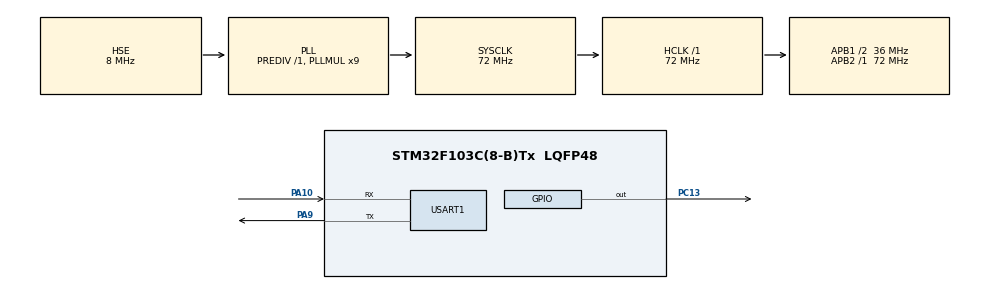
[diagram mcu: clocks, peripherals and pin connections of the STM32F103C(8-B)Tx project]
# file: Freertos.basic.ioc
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Dma.Request0=USART1_RX
Dma.Request1=USART1_TX
Dma.USART1_RX.0.Direction=DMA_PERIPH_TO_MEMORY
Dma.USART1_RX.0.Instance=DMA1_Channel5
Dma.USART1_RX.0.MemDataAlignment=DMA_MDATAALIGN_BYTE
Dma.USART1_RX.0.MemInc=DMA_MINC_ENABLE
Dma.USART1_RX.0.Mode=DMA_NORMAL
Dma.USART1_RX.0.PeriphDataAlignment=DMA_PDATAALIGN_BYTE
Dma.USART1_RX.0.PeriphInc=DMA_PINC_DISABLE
Dma.USART1_RX.0.Priority=DMA_PRIORITY_LOW
Dma.USART1_TX.1.Direction=DMA_MEMORY_TO_PERIPH
Dma.USART1_TX.1.Instance=DMA1_Channel4
Dma.USART1_TX.1.MemDataAlignment=DMA_MDATAALIGN_BYTE
Dma.USART1_TX.1.MemInc=DMA_MINC_ENABLE
Dma.USART1_TX.1.Mode=DMA_NORMAL
Dma.USART1_TX.1.PeriphDataAlignment=DMA_PDATAALIGN_BYTE
Dma.USART1_TX.1.PeriphInc=DMA_PINC_DISABLE
Dma.USART1_TX.1.Priority=DMA_PRIORITY_LOW
FREERTOS.Queues01=myQueue01,16,uint16_t,0,Dynamic,NULL,NULL
FREERTOS.Tasks01=ledTask,24,128,StartledTask,Default,NULL,Dynamic,NULL,NULL;connect_task,24,128,Startconnect_Task,Default,NULL,Dynamic,NULL,NULL
FREERTOS.configUSE_PREEMPTION=0
Mcu.Family=STM32F1
Mcu.Name=STM32F103C(8-B)Tx
Mcu.Package=LQFP48
NVIC.DMA1_Channel4_IRQn=true\:5\:0\:false\:false\:true\:true\:false\:true\:true
NVIC.DMA1_Channel5_IRQn=true\:5\:0\:false\:false\:true\:true\:false\:true\:true
NVIC.PriorityGroup=NVIC_PRIORITYGROUP_4
NVIC.TIM4_IRQn=true\:15\:0\:false\:false\:true\:false\:false\:true\:true
NVIC.TimeBase=TIM4_IRQn
NVIC.TimeBaseIP=TIM4
NVIC.USART1_IRQn=true\:5\:0\:false\:false\:true\:true\:true\:true\:true
PA10.Mode=Asynchronous
PA10.Signal=USART1_RX
PA13.Mode=Serial_Wire
PA13.Signal=SYS_JTMS-SWDIO
PA14.Mode=Serial_Wire
PA14.Signal=SYS_JTCK-SWCLK
PA9.Mode=Asynchronous
PA9.Signal=USART1_TX
PC13-TAMPER-RTC.PinState=GPIO_PIN_RESET
PC13-TAMPER-RTC.Signal=GPIO_Output
PD0-OSC_IN.Mode=HSE-External-Oscillator
PD0-OSC_IN.Signal=RCC_OSC_IN
PD1-OSC_OUT.Mode=HSE-External-Oscillator
PD1-OSC_OUT.Signal=RCC_OSC_OUT
ProjectManager.HeapSize=0x200
ProjectManager.StackSize=0x400
ProjectManager.TargetToolchain=CMake
RCC.AHBFreq_Value=72000000
RCC.APB1CLKDivider=RCC_HCLK_DIV2
RCC.APB1Freq_Value=36000000
RCC.APB1TimFreq_Value=72000000
RCC.APB2Freq_Value=72000000
RCC.APB2TimFreq_Value=72000000
RCC.HCLKFreq_Value=72000000
RCC.PLLMUL=RCC_PLL_MUL9
RCC.PLLSourceVirtual=RCC_PLLSOURCE_HSE
RCC.SYSCLKFreq_VALUE=72000000
RCC.SYSCLKSource=RCC_SYSCLKSOURCE_PLLCLK
RCC.USBFreq_Value=72000000
USART1.VirtualMode=VM_ASYNC
VP_FREERTOS_VS_CMSIS_V2.Mode=CMSIS_V2
VP_SYS_VS_tim4.Mode=TIM4
board=custom

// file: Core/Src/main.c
/* USER CODE BEGIN Header */
/**
  ******************************************************************************
  * @file           : main.c
  * @brief          : Main program body
  ******************************************************************************
  * @attention
  *
  * Copyright (c) 2025 STMicroelectronics.
  * All rights reserved.
  *
  * This software is licensed under terms that can be found in the LICENSE file
  * in the root directory of this software component.
  * If no LICENSE file comes with this software, it is provided AS-IS.
  *
  ******************************************************************************
  */
/* USER CODE END Header */
#include "main.h"
#include "cmsis_os.h"
#include "dma.h"
#include "usart.h"
#include "gpio.h"

void SystemClock_Config(void);
void MX_FREERTOS_Init(void);

int main(void)
{

  /* MCU Configuration--------------------------------------------------------*/

  /* Reset of all peripherals, Initializes the Flash interface and the Systick. */
  HAL_Init();

  /* Configure the system clock */
  SystemClock_Config();

  /* Initialize all configured peripherals */
  MX_GPIO_Init();
  MX_DMA_Init();
  MX_USART1_UART_Init();

  /* Init scheduler */
  osKernelInitialize();  /* Call init function for freertos objects (in cmsis_os2.c) */
  MX_FREERTOS_Init();

  /* Start scheduler */
  osKernelStart();

  /* We should never get here as control is now taken by the scheduler */

  /* Infinite loop */
  while (1)
  {

  }
}

void SystemClock_Config(void)
{
  RCC_OscInitTypeDef RCC_OscInitStruct = {0};
  RCC_ClkInitTypeDef RCC_ClkInitStruct = {0};

  /** Initializes the RCC Oscillators according to the specified parameters
  * in the RCC_OscInitTypeDef structure.
  */
  RCC_OscInitStruct.OscillatorType = RCC_OSCILLATORTYPE_HSE;
  RCC_OscInitStruct.HSEState = RCC_HSE_ON;
  RCC_OscInitStruct.HSEPredivValue = RCC_HSE_PREDIV_DIV1;
  RCC_OscInitStruct.HSIState = RCC_HSI_ON;
  RCC_OscInitStruct.PLL.PLLState = RCC_PLL_ON;
  RCC_OscInitStruct.PLL.PLLSource = RCC_PLLSOURCE_HSE;
  RCC_OscInitStruct.PLL.PLLMUL = RCC_PLL_MUL9;
  if (HAL_RCC_OscConfig(&RCC_OscInitStruct) != HAL_OK)
  {
    Error_Handler();
  }

  /** Initializes the CPU, AHB and APB buses clocks
  */
  RCC_ClkInitStruct.ClockType = RCC_CLOCKTYPE_HCLK|RCC_CLOCKTYPE_SYSCLK
                              |RCC_CLOCKTYPE_PCLK1|RCC_CLOCKTYPE_PCLK2;
  RCC_ClkInitStruct.SYSCLKSource = RCC_SYSCLKSOURCE_PLLCLK;
  RCC_ClkInitStruct.AHBCLKDivider = RCC_SYSCLK_DIV1;
  RCC_ClkInitStruct.APB1CLKDivider = RCC_HCLK_DIV2;
  RCC_ClkInitStruct.APB2CLKDivider = RCC_HCLK_DIV1;

  if (HAL_RCC_ClockConfig(&RCC_ClkInitStruct, FLASH_LATENCY_2) != HAL_OK)
  {
    Error_Handler();
  }
}

void HAL_TIM_PeriodElapsedCallback(TIM_HandleTypeDef *htim)
{
  if (htim->Instance == TIM4)
  {
    HAL_IncTick();
  }
}

void Error_Handler(void)
{
  __disable_irq();
  while (1)
  {
  }
}

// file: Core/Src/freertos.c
/* USER CODE BEGIN Header */
/**
  ******************************************************************************
  * File Name          : freertos.c
  * Description        : Code for freertos applications
  ******************************************************************************
  * @attention
  *
  * Copyright (c) 2025 STMicroelectronics.
  * All rights reserved.
  *
  * This software is licensed under terms that can be found in the LICENSE file
  * in the root directory of this software component.
  * If no LICENSE file comes with this software, it is provided AS-IS.
  *
  ******************************************************************************
  */
/* USER CODE END Header */

#include "FreeRTOS.h"
#include "cmsis_os2.h"
#include "projdefs.h"
#include "task.h"
#include "main.h"
#include "cmsis_os.h"

/* USER CODE BEGIN Includes */
#include "math.h"
#include "usart.h"
#include <stdint.h>
#include "queue.h"
/* USER CODE END Includes */

/* USER CODE BEGIN PTD */
uint8_t rx_buffer[3];
volatile uint8_t rxdone = 0;
/* USER CODE END PTD */

/* Definitions for ledTask */
osThreadId_t ledTaskHandle;
const osThreadAttr_t ledTask_attributes = {
  .name = "ledTask",
  .stack_size = 128 * 4,
  .priority = (osPriority_t) osPriorityNormal,
};
/* Definitions for connect_task */
osThreadId_t connect_taskHandle;
const osThreadAttr_t connect_task_attributes = {
  .name = "connect_task",
  .stack_size = 128 * 4,
  .priority = (osPriority_t) osPriorityNormal,
};
/* Definitions for myQueue01 */
osMessageQueueId_t myQueue01Handle;
const osMessageQueueAttr_t myQueue01_attributes = {
  .name = "myQueue01"
};

void StartledTask(void *argument);
void Startconnect_Task(void *argument);

void MX_FREERTOS_Init(void); /* (MISRA C 2004 rule 8.1) */

void MX_FREERTOS_Init(void) {

  /* Create the queue(s) */
  /* creation of myQueue01 */
  myQueue01Handle = osMessageQueueNew (16, sizeof(uint32_t), &myQueue01_attributes);

  /* Create the thread(s) */
  /* creation of ledTask */
  ledTaskHandle = osThreadNew(StartledTask, NULL, &ledTask_attributes);

  /* creation of connect_task */
  connect_taskHandle = osThreadNew(Startconnect_Task, NULL, &connect_task_attributes);

}

// void UART_connect()
// {
//   __HAL_UART_ENABLE_IT(&huart1, UART_IT_IDLE);
//   HAL_UART_Receive_DMA(&huart1, rx_buffer, 3);
// }

void HAL_UART_RxCpltCallback(UART_HandleTypeDef *huart)
{
  if(huart->Instance == USART1)
  {
    HAL_UART_Transmit_DMA(&huart1, rx_buffer, 3);
    HAL_UART_Receive_DMA(&huart1, rx_buffer, 3);
  }
}

void UART_Address()
{
  uint32_t time = 0;
  int Size = sizeof(rx_buffer) / sizeof(rx_buffer[0]);
    for(int i = Size - 1; i >= 0; i--)
    {
      if(rx_buffer[i] >= '0' && rx_buffer[i] <= '9')
        {
          time += (rx_buffer[i] - '0') * pow(10, (Size - i - 1));
        }
    }
    uint32_t check_time = time;
    //osMessageQueuePut(myQueue01Handle, &time, 0, 0);
    xQueueSend(myQueue01Handle, &check_time, 0);
}

void StartledTask(void *argument)
{
  /* USER CODE BEGIN StartledTask */
  HAL_UART_Receive_DMA(&huart1, rx_buffer, 3);
  /* Infinite loop */
  for(;;)
  {
    UART_Address();
    osDelay(1);
    // osMessageQueueGet(myQueue01Handle, &time, NULL, osWaitForever);
    // HAL_GPIO_TogglePin(GPIOC, GPIO_PIN_13);
    // osDelay(pdMS_TO_TICKS(time));
  }
  /* USER CODE END StartledTask */
}

void Startconnect_Task(void *argument)
{
  /* USER CODE BEGIN Startconnect_Task */
  uint32_t time;
  uint32_t time_get = 500;
  /* Infinite loop */
  for(;;)
  {
    //osMessageQueueGet(myQueue01Handle, &time, NULL, osWaitForever);
    if (xQueueReceive(myQueue01Handle, &time, portMAX_DELAY) == pdTRUE)
    {
      time_get = time;
    }
    HAL_GPIO_TogglePin(GPIOC, GPIO_PIN_13);
    osDelay(pdMS_TO_TICKS(time_get));
    //osDelay(time_get);
  }
  /* USER CODE END Startconnect_Task */
}
